# HC32A4A8RITJ register map
File version: 1.0
CPU: CM4 r0p1, little endian, MPU, FPU, 4 interrupt priority bits
Registers are 32-bit, read-write, reset 0x0 unless marked. A register's access mark holds for its fields unless they carry their own. Offsets are from the block's base; [hi:lo] are bit positions; {n}, {i} and the like mark numbered series.

## TMR61 — desc TMR6
Base 0x40018000
Same registers: TMR62 0x40018400, TMR63 0x40018800, TMR64 0x40018C00
0x00 CNTER
0x04 UPDAR
0x40 PERAR reset 0xFFFFFFFF
0x44 PERBR reset 0xFFFFFFFF
0x48 PERCR reset 0xFFFFFFFF
0x80 GCMAR reset 0xFFFFFFFF
0x84 GCMBR reset 0xFFFFFFFF
0x88 GCMCR reset 0xFFFFFFFF
0x8C GCMDR reset 0xFFFFFFFF
0x90 GCMER reset 0xFFFFFFFF
0x94 GCMFR reset 0xFFFFFFFF
0xC0 SCMAR reset 0xFFFFFFFF
0xC4 SCMBR reset 0xFFFFFFFF
0xC8 SCMCR reset 0xFFFFFFFF
0xCC SCMDR reset 0xFFFFFFFF
0xD0 SCMER reset 0xFFFFFFFF
0xD4 SCMFR reset 0xFFFFFFFF
0x100 DTUAR reset 0xFFFFFFFF
0x104 DTDAR reset 0xFFFFFFFF
0x108 DTUBR reset 0xFFFFFFFF
0x10C DTDBR reset 0xFFFFFFFF
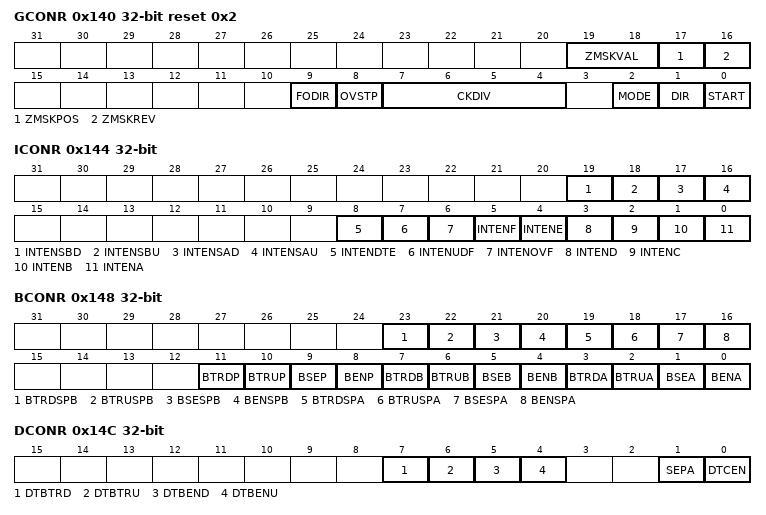
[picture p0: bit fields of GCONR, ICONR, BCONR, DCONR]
0x140 GCONR reset 0x2
  [19:18] ZMSKVAL, [17] ZMSKPOS, [16] ZMSKREV, [9] FODIR, [8] OVSTP, [7:4] CKDIV, [2] MODE, [1] DIR, [0] START
0x144 ICONR
  [19] INTENSBD, [18] INTENSBU, [17] INTENSAD, [16] INTENSAU, [8] INTENDTE, [7] INTENUDF, [6] INTENOVF, [5] INTENF, [4] INTENE, [3] INTEND, [2] INTENC, [1] INTENB, [0] INTENA
0x148 BCONR
  [23] BTRDSPB, [22] BTRUSPB, [21] BSESPB, [20] BENSPB, [19] BTRDSPA, [18] BTRUSPA, [17] BSESPA, [16] BENSPA, [11] BTRDP, [10] BTRUP, [9] BSEP, [8] BENP, [7] BTRDB, [6] BTRUB, [5] BSEB, [4] BENB, [3] BTRDA, [2] BTRUA, [1] BSEA, [0] BENA
0x14C DCONR
  [7] DTBTRD, [6] DTBTRU, [5] DTBEND, [4] DTBENU, [1] SEPA, [0] DTCEN
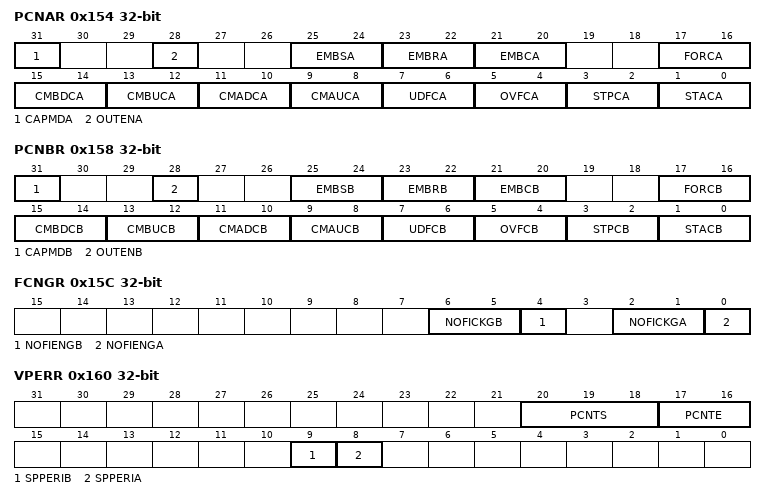
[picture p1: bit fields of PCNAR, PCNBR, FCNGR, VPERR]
0x154 PCNAR
  [31] CAPMDA, [28] OUTENA, [25:24] EMBSA, [23:22] EMBRA, [21:20] EMBCA, [17:16] FORCA, [15:14] CMBDCA, [13:12] CMBUCA, [11:10] CMADCA, [9:8] CMAUCA, [7:6] UDFCA, [5:4] OVFCA, [3:2] STPCA, [1:0] STACA
0x158 PCNBR
  [31] CAPMDB, [28] OUTENB, [25:24] EMBSB, [23:22] EMBRB, [21:20] EMBCB, [17:16] FORCB, [15:14] CMBDCB, [13:12] CMBUCB, [11:10] CMADCB, [9:8] CMAUCB, [7:6] UDFCB, [5:4] OVFCB, [3:2] STPCB, [1:0] STACB
0x15C FCNGR
  [6:5] NOFICKGB, [4] NOFIENGB, [2:1] NOFICKGA, [0] NOFIENGA
0x160 VPERR
  [20:18] PCNTS, [17:16] PCNTE, [9] SPPERIB, [8] SPPERIA
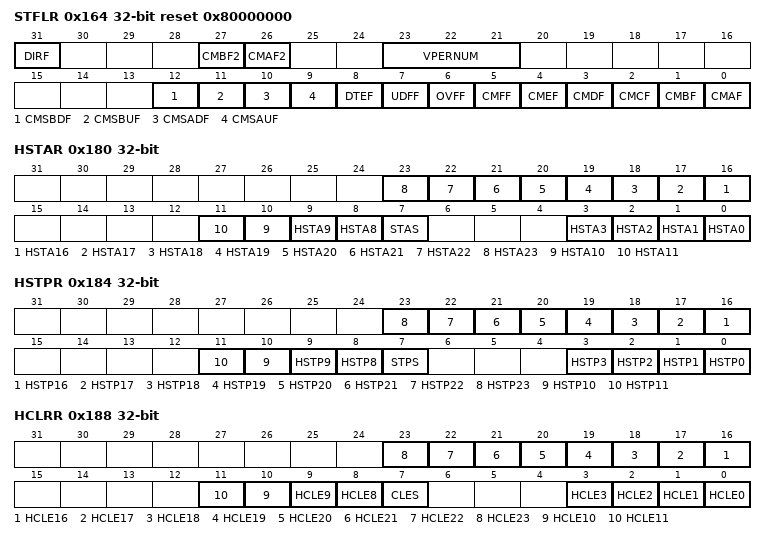
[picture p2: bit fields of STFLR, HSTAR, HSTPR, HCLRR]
0x164 STFLR reset 0x80000000
  [31] DIRF ro, [27] CMBF2, [26] CMAF2, [23:21] VPERNUM ro, [12] CMSBDF, [11] CMSBUF, [10] CMSADF, [9] CMSAUF, [8] DTEF ro, [7] UDFF, [6] OVFF, [5] CMFF, [4] CMEF, [3] CMDF, [2] CMCF, [1] CMBF, [0] CMAF
0x180 HSTAR
  [n] HSTA{n} (n=16..23), [n] HSTA{n} (n=8..11), [7] STAS, [n] HSTA{n} (n=0..3)
0x184 HSTPR
  [n] HSTP{n} (n=16..23), [n] HSTP{n} (n=8..11), [7] STPS, [n] HSTP{n} (n=0..3)
0x188 HCLRR
  [n] HCLE{n} (n=16..23), [n] HCLE{n} (n=8..11), [7] CLES, [n] HCLE{n} (n=0..3)
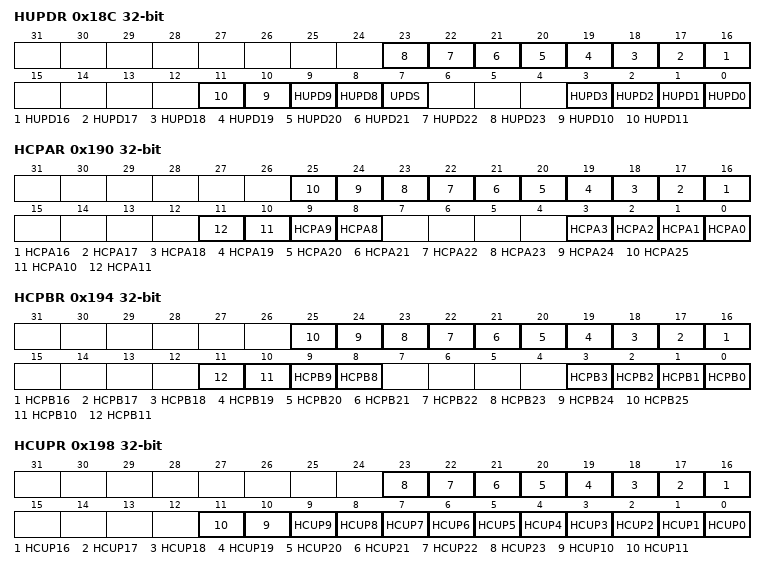
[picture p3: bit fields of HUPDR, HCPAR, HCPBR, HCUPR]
0x18C HUPDR
  [n] HUPD{n} (n=16..23), [n] HUPD{n} (n=8..11), [7] UPDS, [n] HUPD{n} (n=0..3)
0x190 HCPAR
  [n] HCPA{n} (n=16..25), [n] HCPA{n} (n=8..11), [n] HCPA{n} (n=0..3)
0x194 HCPBR
  [n] HCPB{n} (n=16..25), [n] HCPB{n} (n=8..11), [n] HCPB{n} (n=0..3)
0x198 HCUPR
  [n] HCUP{n} (n=16..23), [n] HCUP{n} (n=0..11)
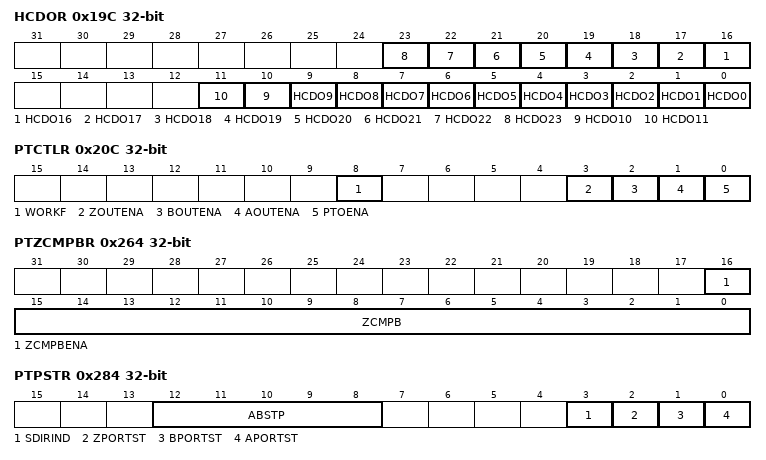
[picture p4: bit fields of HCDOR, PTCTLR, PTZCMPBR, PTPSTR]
0x19C HCDOR
  [n] HCDO{n} (n=16..23), [n] HCDO{n} (n=0..11)
0x200 PTNUMR
0x204 PTPERR
  [15:0] PTPER
0x208 PTRMDR
0x20C PTCTLR
  [8] WORKF ro, [3] ZOUTENA, [2] BOUTENA, [1] AOUTENA, [0] PTOENA
0x220 PTAOPR
  [3:0] PTAOP
0x228 PTBOPR
  [3:0] PTBOP
0x240 PTZOSPR reset 0xFFFFFFFF
0x248 PTZOEPR reset 0xFFFFFFFF
0x264 PTZCMPBR
  [16] ZCMPBENA, [15:0] ZCMPB
0x268 PTZPERR
0x280 PTPSPR
0x284 PTPSTR
  [12:8] ABSTP, [3] SDIRIND, [2] ZPORTST, [1] BPORTST, [0] APORTST
0x290 PTPCPR ro
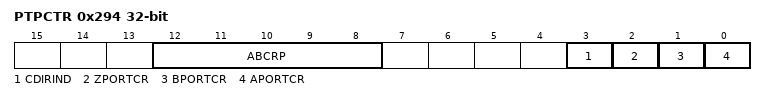
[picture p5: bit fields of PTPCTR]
0x294 PTPCTR ro
  [12:8] ABCRP, [3] CDIRIND, [2] ZPORTCR, [1] BPORTCR, [0] APORTCR

## TMR65 — desc TMR6
Base 0x40019000
Same registers: TMR67 0x40019800
Registers as TMR61; these are added or differ:
0x00 CNTER
  [15:0] CNT
0x04 UPDAR
  [15:0] UPDA
0x40 PERAR reset 0xFFFF
  [15:0] PERA
0x44 PERBR reset 0xFFFF
  [15:0] PERB
0x48 PERCR reset 0xFFFF
  [15:0] PERC
0x80 GCMAR reset 0xFFFF
  [15:0] GCMA
0x84 GCMBR reset 0xFFFF
  [15:0] GCMB
0x88 GCMCR reset 0xFFFF
  [15:0] GCMC
0x8C GCMDR reset 0xFFFF
  [15:0] GCMD
0x90 GCMER reset 0xFFFF
  [15:0] GCME
0x94 GCMFR reset 0xFFFF
  [15:0] GCMF
0xC0 SCMAR reset 0xFFFF
  [15:0] SCMA
0xC4 SCMBR reset 0xFFFF
  [15:0] SCMB
0xC8 SCMCR reset 0xFFFF
  [15:0] SCMC
0xCC SCMDR reset 0xFFFF
  [15:0] SCMD
0xD0 SCMER reset 0xFFFF
  [15:0] SCME
0xD4 SCMFR reset 0xFFFF
  [15:0] SCMF
0x100 DTUAR reset 0xFFFF
  [15:0] DTUA
0x104 DTDAR reset 0xFFFF
  [15:0] DTDA
0x108 DTUBR reset 0xFFFF
  [15:0] DTUB
0x10C DTDBR reset 0xFFFF
  [15:0] DTDB
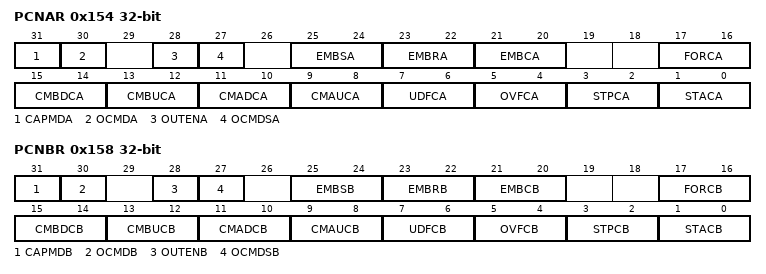
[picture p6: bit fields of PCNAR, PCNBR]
0x154 PCNAR
  [31] CAPMDA, [30] OCMDA, [28] OUTENA, [27] OCMDSA, [25:24] EMBSA, [23:22] EMBRA, [21:20] EMBCA, [17:16] FORCA, [15:14] CMBDCA, [13:12] CMBUCA, [11:10] CMADCA, [9:8] CMAUCA, [7:6] UDFCA, [5:4] OVFCA, [3:2] STPCA, [1:0] STACA
0x158 PCNBR
  [31] CAPMDB, [30] OCMDB, [28] OUTENB, [27] OCMDSB, [25:24] EMBSB, [23:22] EMBRB, [21:20] EMBCB, [17:16] FORCB, [15:14] CMBDCB, [13:12] CMBUCB, [11:10] CMADCB, [9:8] CMAUCB, [7:6] UDFCB, [5:4] OVFCB, [3:2] STPCB, [1:0] STACB
0x220 PTAOPR
  [3:0] PTBOP

## TMR66 — desc TMR6
Base 0x40019400
Same registers: TMR68 0x40019C00
Registers as TMR65, without PTNUMR, PTPERR, PTRMDR, PTCTLR, PTAOPR, PTBOPR, PTZOSPR, PTZOEPR, PTZCMPBR, PTZPERR, PTPSPR, PTPSTR, PTPCPR, PTPCTR.
